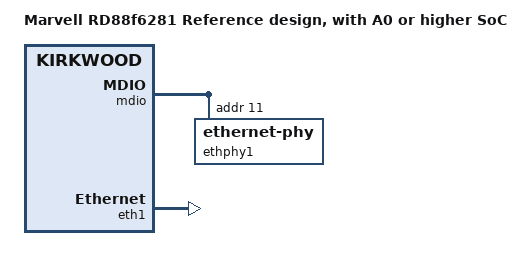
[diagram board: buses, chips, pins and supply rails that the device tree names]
/dts-v1/;
#include "kirkwood-rd88f6281.dtsi"
/ {
	model = "Marvell RD88f6281 Reference design, with A0 or higher SoC";
	compatible = "marvell,rd88f6281-a", "marvell,rd88f6281","marvell,kirkwood-88f6281", "marvell,kirkwood";
};
&mdio {
	status = "okay";
	ethphy1: ethernet-phy@11 {
		 reg = <11>;
	};
};
&switch {
	reg = <10>;
};
&eth1 {
	status = "okay";
	ethernet1-port@0 {
		 phy-handle = <&ethphy1>;
	};
};
